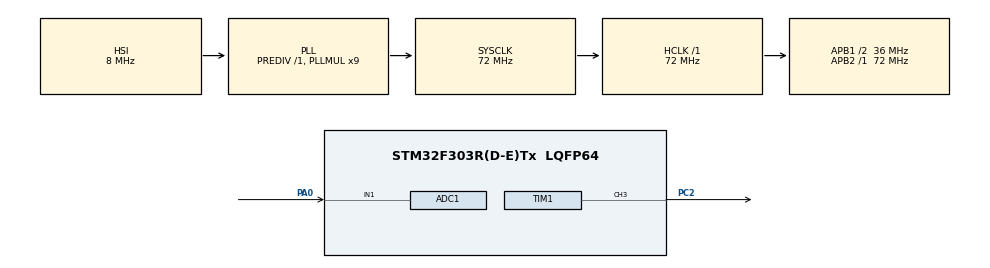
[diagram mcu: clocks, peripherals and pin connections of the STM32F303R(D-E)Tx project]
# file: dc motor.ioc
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ADC1.Channel-0\#ChannelRegularConversion=ADC_CHANNEL_1
ADC1.NbrOfConversionFlag=1
ADC1.Offset-0\#ChannelRegularConversion=0
ADC1.OffsetNumber-0\#ChannelRegularConversion=ADC_OFFSET_NONE
ADC1.Rank-0\#ChannelRegularConversion=1
ADC1.SamplingTime-0\#ChannelRegularConversion=ADC_SAMPLETIME_1CYCLE_5
ADC1.SamplingTimeOPAMP-0\#ChannelRegularConversion=ADC_SAMPLETIME_61CYCLES_5
ADC1.master=1
Mcu.Family=STM32F3
Mcu.Name=STM32F303R(D-E)Tx
Mcu.Package=LQFP64
NVIC.PriorityGroup=NVIC_PRIORITYGROUP_0
PA0.Mode=IN1-Single-Ended
PA0.Signal=ADC1_IN1
PC2.Signal=S_TIM1_CH3
ProjectManager.HeapSize=0x200
ProjectManager.StackSize=0x400
ProjectManager.TargetToolchain=STM32CubeIDE
RCC.AHBFreq_Value=72000000
RCC.APB1CLKDivider=RCC_HCLK_DIV2
RCC.APB1Freq_Value=36000000
RCC.APB1TimFreq_Value=72000000
RCC.APB2Freq_Value=72000000
RCC.APB2TimFreq_Value=72000000
RCC.CortexFreq_Value=72000000
RCC.HCLKFreq_Value=72000000
RCC.HSE_VALUE=8000000
RCC.HSI_VALUE=8000000
RCC.PLLM=8
RCC.PLLMUL=RCC_PLL_MUL9
RCC.PLLN=336
RCC.PLLP=RCC_PLLP_DIV4
RCC.PLLQ=7
RCC.RCC_PLLsource_Clock_Source_FROM_HSE=RCC_HSE_PREDIV_DIV2
RCC.SYSCLKFreq_VALUE=72000000
RCC.SYSCLKSourceVirtual=RCC_SYSCLKSOURCE_PLLCLK
RCC.USBFreq_Value=72000000
SH.S_TIM1_CH3.0=TIM1_CH3,PWM Generation3 CH3
TIM1.Channel-PWM\ Generation3\ CH3=TIM_CHANNEL_3
TIM1.Prescaler=71
board=NUCLEO-F303RE

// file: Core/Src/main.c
/* USER CODE BEGIN Header */
/**
  ******************************************************************************
  * @file           : main.c
  * @brief          : Main program body
  ******************************************************************************
  * @attention
  *
  * Copyright (c) 2025 STMicroelectronics.
  * All rights reserved.
  *
  * This software is licensed under terms that can be found in the LICENSE file
  * in the root directory of this software component.
  * If no LICENSE file comes with this software, it is provided AS-IS.
  *
  ******************************************************************************
  */
/* USER CODE END Header */
#include "main.h"

ADC_HandleTypeDef hadc1;

TIM_HandleTypeDef htim1;

void SystemClock_Config(void);
static void MX_GPIO_Init(void);
static void MX_ADC1_Init(void);
static void MX_TIM1_Init(void);

uint32_t adc_val = 0;

int main(void)
{

  /* MCU Configuration--------------------------------------------------------*/

  /* Reset of all peripherals, Initializes the Flash interface and the Systick. */
  HAL_Init();

  /* Configure the system clock */
  SystemClock_Config();

  /* Initialize all configured peripherals */
  MX_GPIO_Init();
  MX_ADC1_Init();
  MX_TIM1_Init();
  /* USER CODE BEGIN 2 */
  HAL_TIM_Base_Start_IT(&htim1);
  HAL_TIM_PWM_Start(&htim1, TIM_CHANNEL_3);
  /* USER CODE END 2 */

  /* Infinite loop */
  /* USER CODE BEGIN WHILE */
  while (1)
  {
	  HAL_ADC_Start(&hadc1);
	    HAL_ADC_PollForConversion(&hadc1, HAL_MAX_DELAY);
	    adc_val = HAL_ADC_GetValue(&hadc1);  // 0-4095

	    uint32_t pwm_val = (adc_val * __HAL_TIM_GET_AUTORELOAD(&htim1)) / 4095;

	    __HAL_TIM_SET_COMPARE(&htim1, TIM_CHANNEL_3, pwm_val);

	    HAL_Delay(10);  // optional debounce
  }
  /* USER CODE END 3 */
}

void SystemClock_Config(void)
{
  RCC_OscInitTypeDef RCC_OscInitStruct = {0};
  RCC_ClkInitTypeDef RCC_ClkInitStruct = {0};
  RCC_PeriphCLKInitTypeDef PeriphClkInit = {0};

  /** Initializes the RCC Oscillators according to the specified parameters
  * in the RCC_OscInitTypeDef structure.
  */
  RCC_OscInitStruct.OscillatorType = RCC_OSCILLATORTYPE_HSI;
  RCC_OscInitStruct.HSIState = RCC_HSI_ON;
  RCC_OscInitStruct.HSICalibrationValue = RCC_HSICALIBRATION_DEFAULT;
  RCC_OscInitStruct.PLL.PLLState = RCC_PLL_ON;
  RCC_OscInitStruct.PLL.PLLSource = RCC_PLLSOURCE_HSI;
  RCC_OscInitStruct.PLL.PLLMUL = RCC_PLL_MUL9;
  RCC_OscInitStruct.PLL.PREDIV = RCC_PREDIV_DIV1;
  if (HAL_RCC_OscConfig(&RCC_OscInitStruct) != HAL_OK)
  {
    Error_Handler();
  }

  /** Initializes the CPU, AHB and APB buses clocks
  */
  RCC_ClkInitStruct.ClockType = RCC_CLOCKTYPE_HCLK|RCC_CLOCKTYPE_SYSCLK
                              |RCC_CLOCKTYPE_PCLK1|RCC_CLOCKTYPE_PCLK2;
  RCC_ClkInitStruct.SYSCLKSource = RCC_SYSCLKSOURCE_PLLCLK;
  RCC_ClkInitStruct.AHBCLKDivider = RCC_SYSCLK_DIV1;
  RCC_ClkInitStruct.APB1CLKDivider = RCC_HCLK_DIV2;
  RCC_ClkInitStruct.APB2CLKDivider = RCC_HCLK_DIV1;

  if (HAL_RCC_ClockConfig(&RCC_ClkInitStruct, FLASH_LATENCY_2) != HAL_OK)
  {
    Error_Handler();
  }
  PeriphClkInit.PeriphClockSelection = RCC_PERIPHCLK_TIM1|RCC_PERIPHCLK_ADC12;
  PeriphClkInit.Adc12ClockSelection = RCC_ADC12PLLCLK_DIV1;
  PeriphClkInit.Tim1ClockSelection = RCC_TIM1CLK_HCLK;
  if (HAL_RCCEx_PeriphCLKConfig(&PeriphClkInit) != HAL_OK)
  {
    Error_Handler();
  }
}

static void MX_ADC1_Init(void)
{

  ADC_MultiModeTypeDef multimode = {0};
  ADC_ChannelConfTypeDef sConfig = {0};

  /** Common config
  */
  hadc1.Instance = ADC1;
  hadc1.Init.ClockPrescaler = ADC_CLOCK_ASYNC_DIV1;
  hadc1.Init.Resolution = ADC_RESOLUTION_12B;
  hadc1.Init.ScanConvMode = ADC_SCAN_DISABLE;
  hadc1.Init.ContinuousConvMode = DISABLE;
  hadc1.Init.DiscontinuousConvMode = DISABLE;
  hadc1.Init.ExternalTrigConvEdge = ADC_EXTERNALTRIGCONVEDGE_NONE;
  hadc1.Init.ExternalTrigConv = ADC_SOFTWARE_START;
  hadc1.Init.DataAlign = ADC_DATAALIGN_RIGHT;
  hadc1.Init.NbrOfConversion = 1;
  hadc1.Init.DMAContinuousRequests = DISABLE;
  hadc1.Init.EOCSelection = ADC_EOC_SINGLE_CONV;
  hadc1.Init.LowPowerAutoWait = DISABLE;
  hadc1.Init.Overrun = ADC_OVR_DATA_OVERWRITTEN;
  if (HAL_ADC_Init(&hadc1) != HAL_OK)
  {
    Error_Handler();
  }

  /** Configure the ADC multi-mode
  */
  multimode.Mode = ADC_MODE_INDEPENDENT;
  if (HAL_ADCEx_MultiModeConfigChannel(&hadc1, &multimode) != HAL_OK)
  {
    Error_Handler();
  }

  /** Configure Regular Channel
  */
  sConfig.Channel = ADC_CHANNEL_1;
  sConfig.Rank = ADC_REGULAR_RANK_1;
  sConfig.SingleDiff = ADC_SINGLE_ENDED;
  sConfig.SamplingTime = ADC_SAMPLETIME_1CYCLE_5;
  sConfig.OffsetNumber = ADC_OFFSET_NONE;
  sConfig.Offset = 0;
  if (HAL_ADC_ConfigChannel(&hadc1, &sConfig) != HAL_OK)
  {
    Error_Handler();
  }

}

static void MX_TIM1_Init(void)
{

  TIM_MasterConfigTypeDef sMasterConfig = {0};
  TIM_OC_InitTypeDef sConfigOC = {0};
  TIM_BreakDeadTimeConfigTypeDef sBreakDeadTimeConfig = {0};

  htim1.Instance = TIM1;
  htim1.Init.Prescaler = 71;
  htim1.Init.CounterMode = TIM_COUNTERMODE_UP;
  htim1.Init.Period = 65535;
  htim1.Init.ClockDivision = TIM_CLOCKDIVISION_DIV1;
  htim1.Init.RepetitionCounter = 0;
  htim1.Init.AutoReloadPreload = TIM_AUTORELOAD_PRELOAD_DISABLE;
  if (HAL_TIM_PWM_Init(&htim1) != HAL_OK)
  {
    Error_Handler();
  }
  sMasterConfig.MasterOutputTrigger = TIM_TRGO_RESET;
  sMasterConfig.MasterOutputTrigger2 = TIM_TRGO2_RESET;
  sMasterConfig.MasterSlaveMode = TIM_MASTERSLAVEMODE_DISABLE;
  if (HAL_TIMEx_MasterConfigSynchronization(&htim1, &sMasterConfig) != HAL_OK)
  {
    Error_Handler();
  }
  sConfigOC.OCMode = TIM_OCMODE_PWM1;
  sConfigOC.Pulse = 0;
  sConfigOC.OCPolarity = TIM_OCPOLARITY_HIGH;
  sConfigOC.OCNPolarity = TIM_OCNPOLARITY_HIGH;
  sConfigOC.OCFastMode = TIM_OCFAST_DISABLE;
  sConfigOC.OCIdleState = TIM_OCIDLESTATE_RESET;
  sConfigOC.OCNIdleState = TIM_OCNIDLESTATE_RESET;
  if (HAL_TIM_PWM_ConfigChannel(&htim1, &sConfigOC, TIM_CHANNEL_3) != HAL_OK)
  {
    Error_Handler();
  }
  sBreakDeadTimeConfig.OffStateRunMode = TIM_OSSR_DISABLE;
  sBreakDeadTimeConfig.OffStateIDLEMode = TIM_OSSI_DISABLE;
  sBreakDeadTimeConfig.LockLevel = TIM_LOCKLEVEL_OFF;
  sBreakDeadTimeConfig.DeadTime = 0;
  sBreakDeadTimeConfig.BreakState = TIM_BREAK_DISABLE;
  sBreakDeadTimeConfig.BreakPolarity = TIM_BREAKPOLARITY_HIGH;
  sBreakDeadTimeConfig.BreakFilter = 0;
  sBreakDeadTimeConfig.Break2State = TIM_BREAK2_DISABLE;
  sBreakDeadTimeConfig.Break2Polarity = TIM_BREAK2POLARITY_HIGH;
  sBreakDeadTimeConfig.Break2Filter = 0;
  sBreakDeadTimeConfig.AutomaticOutput = TIM_AUTOMATICOUTPUT_DISABLE;
  if (HAL_TIMEx_ConfigBreakDeadTime(&htim1, &sBreakDeadTimeConfig) != HAL_OK)
  {
    Error_Handler();
  }
  HAL_TIM_MspPostInit(&htim1);

}

static void MX_GPIO_Init(void)
{

  /* GPIO Ports Clock Enable */
  __HAL_RCC_GPIOC_CLK_ENABLE();
  __HAL_RCC_GPIOA_CLK_ENABLE();

}

void Error_Handler(void)
{
  __disable_irq();
  while (1)
  {
  }
}
